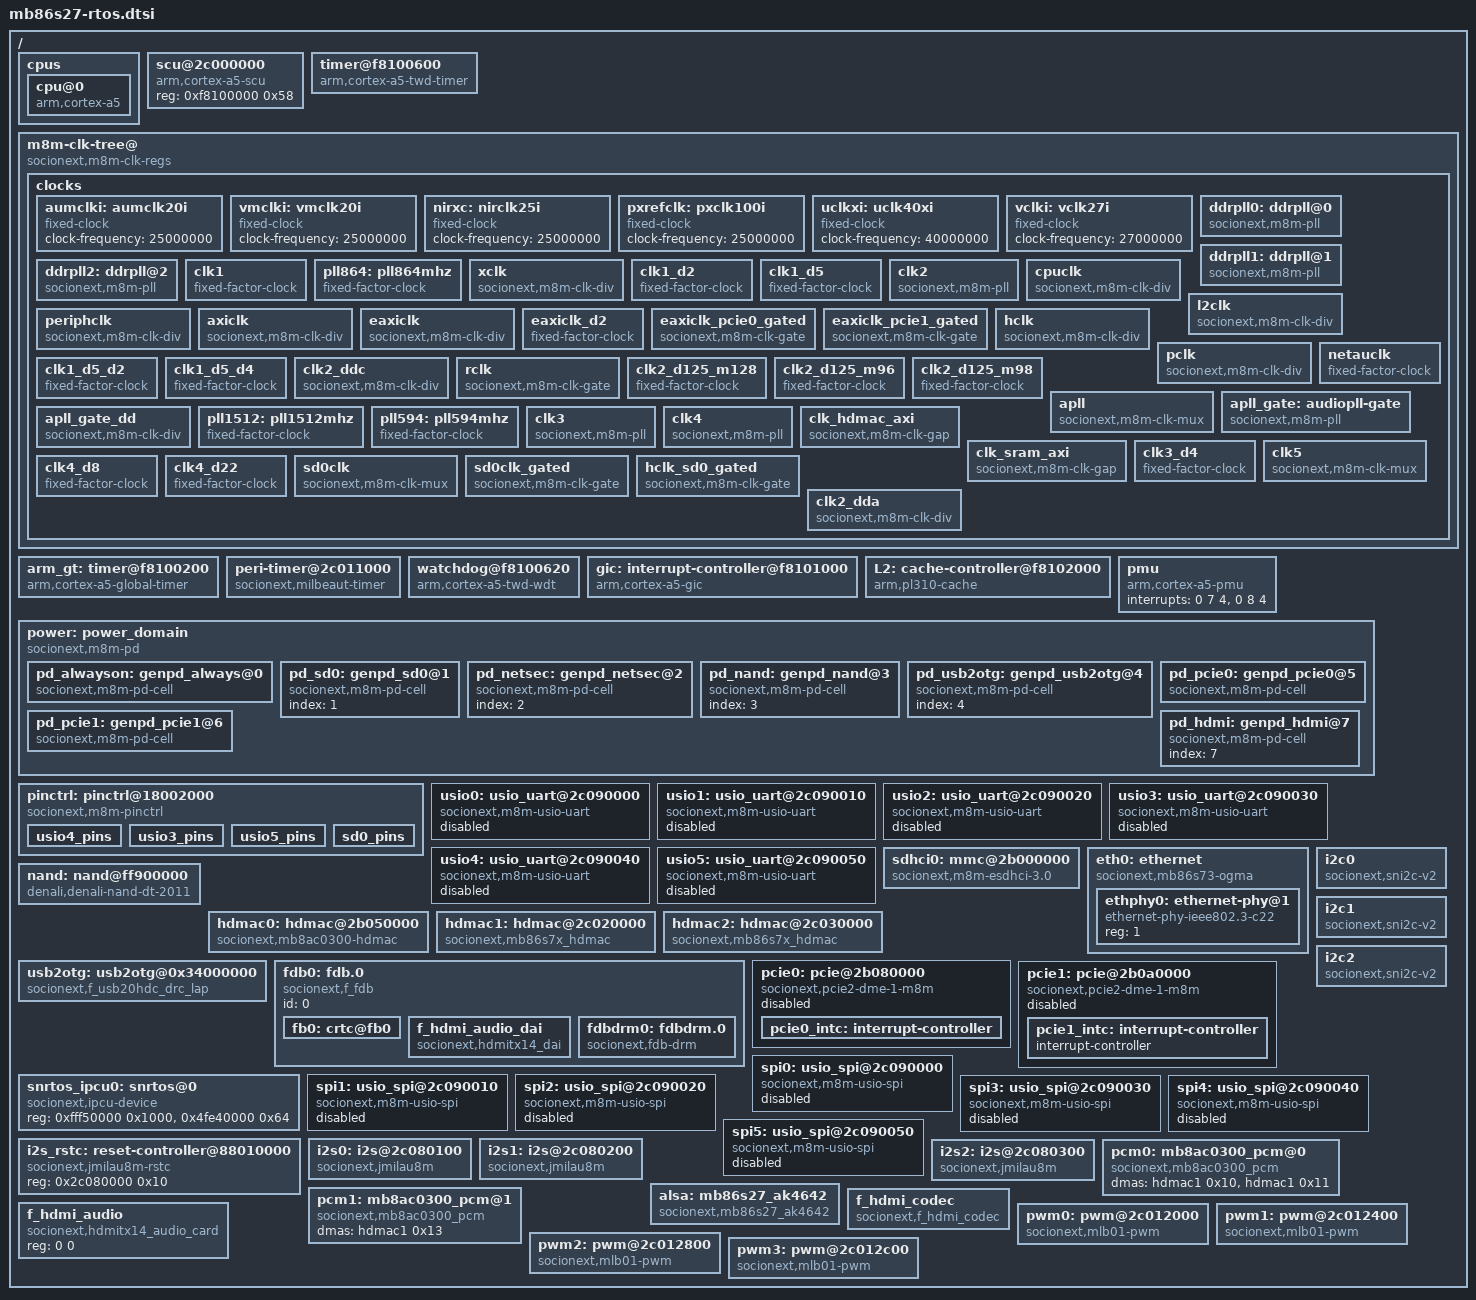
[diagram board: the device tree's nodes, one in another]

#include "skeleton.dtsi"
#include "mb86s27-clk.h"
#include <dt-bindings/interrupt-controller/irq.h>
#include <dt-bindings/gpio/gpio.h>
#include "mb86s27-gpios.h"

/ {
	cpus {
		#address-cells = <1>;
		#size-cells = <0>;
		cpu@0 {
			device_type = "cpu";
			compatible = "arm,cortex-a5";
			reg = <0>;

			operating-points = <
				/* kHz    uV */
				 400000 1000000
				 200000  980000
			>;

			clocks = <&cpuclk>;
			clock-names = "cpu";
			clock-latency = <10000>;

			next-level-cache = <&L2>;
		};
	};

	scu@2c000000 {
		compatible = "arm,cortex-a5-scu";
		reg = <0xf8100000 0x58>;
	};

	timer@f8100600 {
		compatible = "arm,cortex-a5-twd-timer";
		reg = <0xf8100600 0x20>;
		interrupts = <1 13 0x304>;
		clocks = <&periphclk>;
	};

	m8m-clk-tree@ {
		compatible = "socionext,m8m-clk-regs";
		reg = <0x18001000 0x1000>;
		blacklist-clksel = < /* 0x18001000+, '1' = illegal */
			0xff0fffff /* CLKSEL_A */
			0xffffffff /* CLKSEL_B */
			0xffffffff /* CLKSEL_C */
			0xffffffff /* CLKSEL_D */
			0xffe0e0e0 /* CLKSEL_E */
			0xe0e0e0e0 /* CLKSEL_F */
			0xfffffffe /* CLKSEL_G */
			0xffffffff /* CLKSEL_H */
			0xffffffff /* PLLCNTL */
			0xffffffff /* PLLCNTL2 */
			0xffffffff
			0xffffffff
			0xffffffff
			0xffffffff
			0xffffffff
			0xffffffff
			0xffffffff /* CRSWR */
			0xffffffff /* CRRRS */
			0xffffffff /* CRRSM */
		>;
		blacklist-clkstops = < /* 0x18001128+, '1' = illegal */
			0xf3f7bff5 /* CLKSTOPS_A */
			0xfffffcfe /* CLKSTOPS_B */
			0xffffffff /* CLKSTOPS_C */
			0xffffffff /* CLKSTOPS_D */
			0xffffffff /* CLKSTOPS_E */
			0xffffffff /* CLKSTOPS_F */
		>;
		blacklist-clkstopc = < /* 0x18001228+, '1' = illegal */
			0xf3f7bff5 /* CLKSTOPS_A */
			0xfffffcfe /* CLKSTOPS_B */
			0xffffffff /* CLKSTOPS_C */
			0xffffffff /* CLKSTOPS_D */
			0xffffffff /* CLKSTOPS_E */
			0xffffffff /* CLKSTOPS_F */
		>;

		clocks {
			#address-cells = <0>;
			#size-cells = <0>;

			aumclki: aumclk20i {
				compatible = "fixed-clock";
				#clock-cells = <0>;
				clock-frequency = <25000000>;
			};

			vmclki: vmclk20i {
				compatible = "fixed-clock";
				#clock-cells = <0>;
				clock-frequency = <25000000>;
			};

			nirxc: nirclk25i {
				compatible = "fixed-clock";
				#clock-cells = <0>;
				clock-frequency = <25000000>;
			};

			pxrefclk: pxclk100i {
				compatible = "fixed-clock";
				#clock-cells = <0>;
				clock-frequency = <25000000>;
			};

			uclkxi: uclk40xi {
				compatible = "fixed-clock";
				#clock-cells = <0>;
				clock-frequency = <40000000>;
			};

			vclki: vclk27i {
				compatible = "fixed-clock";
				#clock-cells = <0>;
				clock-frequency = <27000000>;
			};

			ddrpll0: ddrpll@0 {
				compatible = "socionext,m8m-pll";
				#clock-cells = <0>;
				offset = <bDDRPLL0ST>;
				rate-control = <bDDRPLL0SEL>;
				clocks = <&uclkxi>;
			};

			ddrpll1: ddrpll@1 {
				compatible = "socionext,m8m-pll";
				#clock-cells = <0>;
				offset = <bDDRPLL1ST>;
				rate-control = <bDDRPLL1SEL>;
				clocks = <&uclkxi>;
			};

			ddrpll2: ddrpll@2 {
				compatible = "socionext,m8m-pll";
				#clock-cells = <0>;
				offset = <bDDRPLL2ST>;
				rate-control = <bDDRPLL2SEL>;
				clocks = <&uclkxi>;
			};
/*
			cecclk: cecclk {
				compatible = "fixed-factor-clock";
				#clock-cells = <0>;
				clock-div = <20>;
				clock-mult = <1>;
				clocks = <&uclkxi>;
			};

			cecclk_gated: cecclk_gated {
				compatible = "socionext,m8m-clk-gate";
				#clock-cells = <0>;
				offset = <bCECCLK>;
				clocks = <&cecclk>;
			};
*/
			clk1: clk1 {
				compatible = "fixed-factor-clock";
				#clock-cells = <0>;
				clock-div = <2>;
				clock-mult = <100>;
				clocks = <&uclkxi>;
			};

			pll864: pll864mhz {
				compatible = "fixed-factor-clock";
				#clock-cells = <0>;
				clock-div = <5>;
				clock-mult = <108>;
				clocks = <&uclkxi>;
			};

			xclk: xclk {
				compatible = "socionext,m8m-clk-div";
				#clock-cells = <0>;
				offset = <bXCLK>;
				mask = <0x3>;
				ratios = <8 0x7 6 0x5 5 0x4>;
				clocks = <&clk1>;
			};

/*			dspclk: dspclk {
				compatible = "socionext,m8m-clk-div";
				#clock-cells = <0>;
				offset = <bDSPCLK>;
				mask = <0xf>;
				ratios = <12 0x1b 11 0x1a 10 0x19 9 0x18 8 0x17 7 0x16 6 0x15>;
				clocks = <&clk1>;
			};
*/
			clk1_d2: clk1_d2 {
				compatible = "fixed-factor-clock";
				#clock-cells = <0>;
				clock-div = <2>;
				clock-mult = <1>;
				clocks = <&clk1>;
			};

			clk1_d5: clk1_d5 {
				compatible = "fixed-factor-clock";
				#clock-cells = <0>;
				clock-div = <5>;
				clock-mult = <1>;
				clocks = <&clk1>;
			};

			clk2: clk2 {
				compatible = "socionext,m8m-pll";
				#clock-cells = <0>;
				offset = <bPLL864ST>;
				clocks = <&pll864>;
			};

			cpuclk: cpuclk {
				compatible = "socionext,m8m-clk-div";
				#clock-cells = <0>;
				offset = <bCPUCLK>;
				mask = <0xf>;
				wait-on-dchreq;
				ratios = <6 0x15 4 0x13 3 0x12 2 0x11 1 0x10>;
				clocks = <&xclk>;
			};

			l2clk: l2clk {
				compatible = "socionext,m8m-clk-div";
				#clock-cells = <0>;
				offset = <bL2CLK>;
				mask = <0xf>;
				wait-on-dchreq;
				ratios = <6 0x15 4 0x13 3 0x12 2 0x11>;
				clocks = <&xclk>;
			};

			periphclk: periphclk {
				compatible = "socionext,m8m-clk-div";
				#clock-cells = <0>;
				offset = <bPERICLK>;
				mask = <0xf>;
				wait-on-dchreq;
				ratios = <12 0x1b 8 0x17 6 0x15 4 0x13>;
				clocks = <&xclk>;
			};

			axiclk: axiclk {
				compatible = "socionext,m8m-clk-div";
				#clock-cells = <0>;
				offset = <bAXICLK>;
				mask = <0xf>;
				wait-on-dchreq;
				ratios = <6 0x15 4 0x13 3 0x12 2 0x11>;
				clocks = <&xclk>;
			};

			eaxiclk: eaxiclk {
				compatible = "socionext,m8m-clk-div";
				#clock-cells = <0>;
				offset = <bEAXICLK>;
				mask = <0xf>;
				wait-on-dchreq;
				ratios = <6 0x15 4 0x13 3 0x12 2 0x11>;
				clocks = <&xclk>;
			};

			eaxiclk_d2: eaxiclk_d2 {
				compatible = "fixed-factor-clock";
				#clock-cells = <0>;
				clock-div = <2>;
				clock-mult = <1>;
				clocks = <&eaxiclk>;
			};

			eaxiclk_pcie0_gated: eaxiclk_pcie0_gated {
				compatible = "socionext,m8m-clk-gate";
				#clock-cells = <0>;
				offset = <bPCIE0AX>;
				clocks = <&eaxiclk>;
			};

			eaxiclk_pcie1_gated: eaxiclk_pcie1_gated {
				compatible = "socionext,m8m-clk-gate";
				#clock-cells = <0>;
				offset = <bPCIE1AX>;
				clocks = <&eaxiclk>;
			};

			hclk: hclk {
				compatible = "socionext,m8m-clk-div";
				#clock-cells = <0>;
				offset = <bAHBCLK>;
				mask = <0xf>;
				wait-on-dchreq;
				ratios = <6 0x15 4 0x13 3 0x12>;
				clocks = <&xclk>;
			};

			pclk: pclk {
				compatible = "socionext,m8m-clk-div";
				#clock-cells = <0>;
				offset = <bAPBCLK>;
				mask = <0xf>;
				wait-on-dchreq;
				ratios = <12 0x1b 8 0x17 6 0x15>;
				clocks = <&xclk>;
			};

			netauclk: netauclk {
				compatible = "fixed-factor-clock";
				#clock-cells = <0>;
				clock-div = <8>;
				clock-mult = <1>;
				clocks = <&clk1_d2>;
			};
/*
			clk1_d2_cd: clk1_d2_cd {
				compatible = "socionext,m8m-clk-fine-div";
				#clock-cells = <0>;
				offset = <bPROCLK>;
				mask = <0x3f>;
				ratios = <75 5>;
				clocks = <&clk1_d2>;
			};
*/
			clk1_d5_d2: clk1_d5_d2 {
				compatible = "fixed-factor-clock";
				#clock-cells = <0>;
				clock-div = <2>;
				clock-mult = <1>;
				clocks = <&clk1_d5>;
			};

			clk1_d5_d4: clk1_d5_d4 {
				compatible = "fixed-factor-clock";
				#clock-cells = <0>;
				clock-div = <4>;
				clock-mult = <1>;
				clocks = <&clk1_d5>;
			};
/*
			clk1_d5_ddb: clk1_d5_ddb {
				compatible = "socionext,m8m-clk-div";
				#clock-cells = <0>;
				offset = <bSD1U1CLK>;
				mask = <0x7>;
				ratios = <4 0x8 2 0x9>;
				clocks = <&clk1_d5>;
			};

			sd1u1clk_gated: sd1u1clk_gated {
				compatible = "socionext,m8m-clk-gate";
				#clock-cells = <0>;
				offset = <bSD1U1CK>;
				clocks = <&clk1_d5_ddb>;
			};

			eaxiclk_sd1_gated: eaxiclk_sd1_gated {
				compatible = "socionext,m8m-clk-gate";
				#clock-cells = <0>;
				offset = <bSD1AX>;
				clocks = <&eaxiclk>;
			};

			clk1_d5_d2_cga: clk1_d5_d2_cga {
				compatible = "socionext,m8m-clk-gap";
				#clock-cells = <0>;
				offset = <bSROCLK>;
				clocks = <&clk1_d5_d2>;
			};

			clk1_d5_d2_cgb: clk1_d5_d2_cgb {
				compatible = "socionext,m8m-clk-gap";
				#clock-cells = <0>;
				offset = <bB2YCLK>;
				or-mask = <2>;
				clocks = <&clk1_d5_d2>;
			};

			clk1_d5_d2_cgc: clk1_d5_d2_cgc {
				compatible = "socionext,m8m-clk-gap";
				#clock-cells = <0>;
				offset = <bWDRCLK>;
				clocks = <&clk1_d5_d2>;
			};

			clk1_d5_d2_cgd: clk1_d5_d2_cgd {
				compatible = "socionext,m8m-clk-gap";
				#clock-cells = <0>;
				offset = <bAHIPCLK>;
				clocks = <&clk1_d5_d2>;
			};

			clk1_d5_d2_cge: clk1_d5_d2_cge {
				compatible = "socionext,m8m-clk-gap";
				#clock-cells = <0>;
				offset = <bJHDRCLK>;
				clocks = <&clk1_d5_d2>;
			};

			clk1_d5_d4_cg: clk1_d5_d4_cg {
				compatible = "socionext,m8m-clk-gap";
				#clock-cells = <0>;
				offset = <bJPGCLK>;
				clocks = <&clk1_d5_d4>;
			};

			clk2_ddb: clk2_ddb {
				compatible = "socionext,m8m-clk-div";
				#clock-cells = <0>;
				offset = <bSENCLK>;
				mask = <0x3>;
				ratios = <128 0x7 64 0x6 32 0x5 28 0x4>;
				clocks = <&clk2>;
			};
			*/
			clk2_ddc: clk2_ddc {
				compatible = "socionext,m8m-clk-div";
				#clock-cells = <0>;
				offset = <bRCLK>;
				mask = <0x3>;
				ratios = <64 0x4 48 0x5 32 0x6 16 0x7>;
				default = <64>;
				clocks = <&clk2>;
			};
			rclk: rclk {
				compatible = "socionext,m8m-clk-gate";
				#clock-cells = <0>;
				offset = <bRCK>;
				clocks = <&clk2_ddc>;
			};
/*
			i2cclk: i2cclk {
				compatible = "fixed-factor-clock";
				#clock-cells = <0>;
				clock-div = <2>;
				clock-mult = <1>;
				clocks = <&rclk>;
			};
			clk2_ddd: clk2_ddd {
				compatible = "socionext,m8m-clk-div";
				#clock-cells = <0>;
				offset = <bAPCLKO>;
				mask = <0x1f>;
				ratios = <16 0x38 12 0x39>;
				clocks = <&clk2>;
			};
*/
			clk2_d125_m128: clk2_d125_m128 {
				compatible = "fixed-factor-clock";
				#clock-cells = <0>;
				clock-div = <125>;
				clock-mult = <128>;
				clocks = <&clk2>;
			};

			clk2_d125_m96: clk2_d125_m96 {
				compatible = "fixed-factor-clock";
				#clock-cells = <0>;
				clock-div = <125>;
				clock-mult = <96>;
				clocks = <&clk2>;
			};

			clk2_d125_m98: clk2_d125_m98 {
				compatible = "fixed-factor-clock";
				#clock-cells = <0>;
				clock-div = <125>;
				clock-mult = <98>;
				clocks = <&clk2>;
			};

			apll: apll { // model the pll as a mux 
				compatible = "socionext,m8m-clk-mux";
				#clock-cells = <0>;
				offset = <bAPLSEL>;
				clocks = <&clk2_d125_m128>,
					 <&clk2_d125_m96>,
					 <&clk2_d125_m98>;
				mux = <0x0 0x2 0x3>;
				mask = <0x3>;
			};

			apll_gate: audiopll-gate {
				compatible = "socionext,m8m-pll";
				#clock-cells = <0>;
				offset = <bAPLLST>;
				clocks = <&apll>;
			};


			apll_gate_dd: apll_gate_dd {
				compatible = "socionext,m8m-clk-div";
				#clock-cells = <0>;
				offset = <bAPLCLK>;
				mask = <0x3>;
				ratios = <108 0x4 36 0x6 30 0x5 18 0x7>;
				clocks = <&apll_gate>;
			};
			pll1512: pll1512mhz {
				compatible = "fixed-factor-clock";
				#clock-cells = <0>;
				clock-div = <1>;
				clock-mult = <56>;
				clocks = <&vclki>;
			};

			pll594: pll594mhz {
				compatible = "fixed-factor-clock";
				#clock-cells = <0>;
				clock-div = <1>;
				clock-mult = <22>;
				clocks = <&vclki>;
			};

			clk3: clk3 {
				compatible = "socionext,m8m-pll";
				#clock-cells = <0>;
				offset = <bPLL1512ST>;
				clocks = <&pll1512>;
			};

			clk4: clk4 {
				compatible = "socionext,m8m-pll";
				#clock-cells = <0>;
				offset = <bPLL594ST>;
				clocks = <&pll594>;
			};
/*

			clk3_dda: clk3_dda {
				compatible = "socionext,m8m-clk-div";
				#clock-cells = <0>;
				offset = <bNFCLK>;
				mask = <0x1>;
				ratios = <4 0x2 2 0x3>;
				default = <2>;
				clocks = <&clk3>;
			};

			clk_axinf: clk_axinf {
				compatible = "socionext,m8m-clk-gap";
				#clock-cells = <0>;
				offset = <bNFAX>;
				clocks = <&axiclk>;
			};
			clk_xdmac_axi: clk_xdmac_axi {
				compatible = "socionext,m8m-clk-gap";
				#clock-cells = <0>;
				offset = <bXDMEAX>;
				clocks = <&axiclk>;
			};
*/
			clk_hdmac_axi: clk_hdmac_axi {
				compatible = "socionext,m8m-clk-gap";
				#clock-cells = <0>;
				offset = <bHDMEAH>;
				clocks = <&axiclk>;
			};

			clk_sram_axi: clk_sram_axi {
				compatible = "socionext,m8m-clk-gap";
				#clock-cells = <0>;
				offset = <bSRAMAX>;
				clocks = <&axiclk>;
			};


			clk3_d4: clk3_d4 {
				compatible = "fixed-factor-clock";
				#clock-cells = <0>;
				clock-div = <4>;
				clock-mult = <1>;
				clocks = <&clk3>;
			};
/*
			clk3_d3: clk3_d3 {
				compatible = "fixed-factor-clock";
				#clock-cells = <0>;
				clock-div = <3>;
				clock-mult = <1>;
				clocks = <&clk3>;
			};

			clk3_d3_dd: clk3_d3_dd {
				compatible = "socionext,m8m-clk-div";
				#clock-cells = <0>;
				offset = <bAPCLKO>;
				mask = <0x1f>;
				ratios = <18 0x30 8 0x31>;
				clocks = <&clk3_d3>;
			};

			clk3_d2: clk3_d2 {
				compatible = "fixed-factor-clock";
				#clock-cells = <0>;
				clock-div = <2>;
				clock-mult = <1>;
				clocks = <&clk3>;
			};

			clk3_d2_d30: clk3_d2_d30 {
				compatible = "fixed-factor-clock";
				#clock-cells = <0>;
				clock-div = <30>;
				clock-mult = <1>;
				clocks = <&clk3_d2>;
			};

			clk3_d2_cda: clk3_d2_cda {
				compatible = "socionext,m8m-clk-fine-div";
				#clock-cells = <0>;
				offset = <bLCDCLK>;
				mask = <0x3f>;
				ratios = <128 14>;
				default = <128>;
				clocks = <&clk3_d2>;
			};
			clk3_d2_cdb: clk3_d2_cdb {
				compatible = "socionext,m8m-clk-fine-div";
				#clock-cells = <0>;
				offset = <bSD1U2CLK>;
				mask = <0x1f>;
				ratios = <29 15>;
				delta = <0x20>;
				clocks = <&clk3_d2>;
			};

			sd1u2clk_gated: sd1u2clk_gated {
				compatible = "socionext,m8m-clk-gate";
				#clock-cells = <0>;
				offset = <bSD1U2CK>;
				clocks = <&clk3_d2_cdb>;
			};
			clk3_d2_cdc: clk3_d2_cdc {
				compatible = "socionext,m8m-clk-fine-div";
				#clock-cells = <0>;
				offset = <bPROCLK>;
				mask = <0x3f>;
				ratios = <75 4>;
				clocks = <&clk3_d2>;
			};

			clk3_d6: clk3_d6 {
				compatible = "fixed-factor-clock";
				#clock-cells = <0>;
				clock-div = <6>;
				clock-mult = <1>;
				clocks = <&clk3>;
			};

			clk3_d6_cga: clk3_d6_cga {
				compatible = "socionext,m8m-clk-gap";
				#clock-cells = <0>;
				offset = <bSROCLK>;
				clocks = <&clk3_d6>;
			};

			clk3_d6_cgb: clk3_d6_cgb {
				compatible = "socionext,m8m-clk-gap";
				#clock-cells = <0>;
				offset = <bSPRCLK>;
				clocks = <&clk3_d6>;
			};

			clk3_d6_cgc: clk3_d6_cgc {
				compatible = "socionext,m8m-clk-gap";
				#clock-cells = <0>;
				offset = <bIIPCLK>;
				clocks = <&clk3_d6>;
			};

			clk3_d6_cgd: clk3_d6_cgd {
				compatible = "socionext,m8m-clk-gap";
				#clock-cells = <0>;
				offset = <bELA0CLK>;
				clocks = <&clk3_d6>;
			};

			clk3_d6_cge: clk3_d6_cge {
				compatible = "socionext,m8m-clk-gap";
				#clock-cells = <0>;
				offset = <bELA1CLK>;
				clocks = <&clk3_d6>;
			};

			clk3_d6_cgf: clk3_d6_cgf {
				compatible = "socionext,m8m-clk-gap";
				#clock-cells = <0>;
				offset = <bDPPCLK>;
				clocks = <&clk3_d6>;
			};

			clk3_d6_cgg: clk3_d6_cgg {
				compatible = "socionext,m8m-clk-gap";
				#clock-cells = <0>;
				offset = <bSRRCLK>;
				clocks = <&clk3_d6>;
			};

			clk3_d6_cgh: clk3_d6_cgh {
				compatible = "socionext,m8m-clk-gap";
				#clock-cells = <0>;
				offset = <bAHFDCLK>;
				clocks = <&clk3_d6>;
			};

			clk4_dda: clk4_dda {
				compatible = "socionext,m8m-clk-div";
				#clock-cells = <0>;
				offset = <bAPCLKO>;
				mask = <0x1f>;
				ratios = <55 0x20 52 0x21 50 0x22 24 0x23 21 0x24 16 0x25 15 0x26 14 0x27 13 0x28 12 0x29 10 0x2a 8 0x2b>;
				clocks = <&clk4>;
			};

			clk4_d2: clk4_d2 {
				compatible = "fixed-factor-clock";
				#clock-cells = <0>;
				clock-div = <2>;
				clock-mult = <1>;
				clocks = <&clk4>;
			};

			clk4_d2_cg: clk4_d2_cg {
				compatible = "socionext,m8m-clk-gap";
				#clock-cells = <0>;
				offset = <bSROCLK>;
				clocks = <&clk4_d2>;
			};

			aplclk0: aplclk0 {
				compatible = "socionext,m8m-clk-mux";
				#clock-cells = <0>;
				offset = <bAU0CKSEL>;
				clocks = <&apll_gate_dd>, <&aumclki>;
				mux = <0x2 0x3>;
				mask = <0x1>;
			};

			aplclk1: aplclk1 {
				compatible = "socionext,m8m-clk-mux";
				#clock-cells = <0>;
				offset = <bAU1CKSEL>;
				clocks = <&apll_gate_dd>, <&aumclki>;
				mux = <0x2 0x3>;
				mask = <0x1>;
			};

			aplclk2: aplclk2 {
				compatible = "socionext,m8m-clk-mux";
				#clock-cells = <0>;
				offset = <bAU2CKSEL>;
				clocks = <&apll_gate_dd>, <&aumclki>;
				mux = <0x2 0x3>;
				mask = <0x1>;
			};

			aplclk0_gated: aplclk0_gated {
				compatible = "socionext,m8m-clk-gate";
				#clock-cells = <0>;
				offset = <bAU0CK>;
				clocks = <&aplclk0>;
			};

			aplclk1_gated: aplclk1_gated {
				compatible = "socionext,m8m-clk-gate";
				#clock-cells = <0>;
				offset = <bAU1CK>;
				clocks = <&aplclk1>;
			};

			aplclk2_gated: aplclk2_gated {
				compatible = "socionext,m8m-clk-gate";
				#clock-cells = <0>;
				offset = <bAU2CK>;
				clocks = <&aplclk2>;
			};
			dispax: dispax {
				compatible = "socionext,m8m-clk-gate";
				#clock-cells = <0>;
				offset = <bDISPAX>;
				clocks = <&axiclk>;
			};
			dispah: dispah {
				compatible = "socionext,m8m-clk-gate";
				#clock-cells = <0>;
				offset = <bDISPAH>;
				clocks = <&axiclk>;
			};
			dispap: dispap {
				compatible = "socionext,m8m-clk-gate";
				#clock-cells = <0>;
				offset = <bDISPAP>;
				clocks = <&axiclk>;
			};
*/
			clk5: clk5 {
				compatible = "socionext,m8m-clk-mux";
				#clock-cells = <0>;
				offset = <bNETAUCKSEL>;
				clocks = <&apll_gate_dd>, <&aumclki>;
				mux = <0x2 0x3>;
				mask = <0x1>;
			};
/*
			lcdclk: lcdclk {
				compatible = "socionext,m8m-clk-mux";
				#clock-cells = <0>;
				offset = <bLCDSEL>;
				clocks = <&clk3_d2_cda>, <&vmclki>, <&vclki>;
				mux = <0x4 0x6 0x7>;
				mask = <0x3>;
			};
			lcdclk_gated: lcdclk_gated {
				compatible = "socionext,m8m-clk-gate";
				#clock-cells = <0>;
				offset = <bLCDCK>;
				clocks = <&lcdclk>;
			};
*/

			clk4_d8: clk4_d8 {
				compatible = "fixed-factor-clock";
				#clock-cells = <0>;
				clock-div = <22>;
				clock-mult = <1>;
				clocks = <&clk4>;
			};

			clk4_d22: clk4_d22 {
				compatible = "fixed-factor-clock";
				#clock-cells = <0>;
				clock-div = <22>;
				clock-mult = <1>;
				clocks = <&clk4>;
			};

/*
			hifclk: hifclk {
				compatible = "socionext,m8m-clk-mux";
				#clock-cells = <0>;
				offset = <bHIFCLK>;
				clocks = <&clk4_d8>, <&clk4_d22>, <&clk3_d2_d30>, <&vmclki>, <&vclki>;
				mux = <0x8 0x9 0xa 0xc 0xe>;
				mask = <0x7>;
			};
			hifclk_gated: hifclk_gated {
				compatible = "socionext,m8m-clk-gate";
				#clock-cells = <0>;
				offset = <bHIFCK>;
				clocks = <&hifclk>;
			};
*/

			sd0clk: sd0clk {
				compatible = "socionext,m8m-clk-mux";
				#clock-cells = <0>;
				offset = <bSD0CLK>;
				clocks = <&clk1_d5_d4>, <&clk4>, <&clk3_d4>, <&clk1_d5_d2>;
				mux = <0x8 0xc 0xa 0x9>;
				mask = <0x7>;
			};

			sd0clk_gated: sd0clk_gated {
				compatible = "socionext,m8m-clk-gate";
				#clock-cells = <0>;
				offset = <bSD0CK>;
				clocks = <&sd0clk>;
			};

			hclk_sd0_gated: hclk_sd0_gated {
				compatible = "socionext,m8m-clk-gate";
				#clock-cells = <0>;
				offset = <bSD0AH>;
				clocks = <&hclk>;
			};

			clk2_dda: clk2_dda {
				compatible = "socionext,m8m-clk-div";
				#clock-cells = <0>;
				offset = <bRIBCLK>;
				mask = <0xf>;
				ratios = <64 0x10 32 0x11 16 0x12 8 0x13 4 0x14>;
				clocks = <&clk2>;
			};
/*
			clk3_ddb: clk3_ddb {
				compatible = "socionext,m8m-clk-div";
				#clock-cells = <0>;
				offset = <bRIBCLK>;
				mask = <0xf>;
				ratios = <12 0x18 8 0x19 6 0x1a 5 0x1b>;
				clocks = <&clk3>;
			};
			ribclk: ribclk {
				compatible = "socionext,m8m-clk-mux";
				#clock-cells = <0>;
				clocks = <&clk2_dda>, <&clk3_ddb>;
			};

			apclko0: apclko0 {
				compatible = "socionext,m8m-clk-mux";
				#clock-cells = <0>;
				clocks = <&clk2_ddd>, <&clk4_dda>, <&clk3_d3_dd>;
			};

			proclk: proclk {
				compatible = "socionext,m8m-clk-mux";
				#clock-cells = <0>;
				offset = <bPROMUX>;
				clocks = <&clk1_d2_cd>, <&clk3_d2_cdc>;
				mux = <0x2 0x3>;
				mask = <0x1>;
			};

			srosel: srosel {
				compatible = "socionext,m8m-clk-mux";
				#clock-cells = <0>;
				offset = <bSROSEL>;
				clocks = <&clk4_d2_cg>, <&proclk>, <&clk3_d6_cga>, <&clk1_d5_d2_cga>;
				mux = <0x4 0x5 0x6 0x7>;
				mask = <0x3>;
			};

			b2yclk: b2yclk {
				compatible = "socionext,m8m-clk-mux";
				#clock-cells = <0>;
				offset = <bB2YCLK>;
				clocks = <&clk1_d5_d2_cgb>, <&proclk>;
				mux = <0x0 0x18>;
				mask = <0xf>;
			};
*/
		};
	};

	arm_gt: timer@f8100200 {
		compatible = "arm,cortex-a5-global-timer",
		             "arm,cortex-a9-global-timer";
		reg = <0xf8100200 0x20>;
		interrupts = <1 11 0x304>;
		clocks = <&periphclk>;
	};

	peri-timer@2c011000 {
		compatible = "socionext,milbeaut-timer";
		reg = <0x2c011050 0x10>, <0x2c011060 0x10>;
		interrupts = <0 127 4>;
		clocks = <&clk2_dda>; /* RIBCLK */
	};

	watchdog@f8100620 {
		compatible = "arm,cortex-a5-twd-wdt";
		reg = <0xf8100620 0x20>;
		interrupts = <1 14 0x304>;
	};

	gic: interrupt-controller@f8101000 {
		compatible = "arm,cortex-a5-gic", "arm,cortex-a9-gic";
		#interrupt-cells = <3>;
		#address-cells = <0>;
		interrupt-controller;
		reg = <0xf8101000 0x1000>,
		      <0xf8100100 0x100>;
		black-list = <0 1 2 3 4 5 6 7 8 9 10 11 12 13 14 15 16 17 18 19 20 21 22 23 24 25 26 27 28 29 30 31 32 33 34 35 36 37 38 39 40 41 42 43 44 45 46 47 48 49 50 51 52 53 54 55 56 57 58 59 60 61 62 63 64 65 66 67 68 69 70 71 72 73 74 75 76 77 78 79 80 81 82 83 84 85 86 87 88 89 90 91 92 93 94 95 96 97 98 99 100 101 102 103 104 105 106 107 108 109 110 111 112 113 114 115 116 117 118 119 120 121 122 123 124 125 126 127 128 129 130 131 132 133 134 135 136 137 138 139 140 141 142 143 144 145 146 147 148 149 150 151 152 153 154 155 156 157 158 159 160 161 162 163 164 165 166 167 168 169 170 171 172 173 174 175 176 177 178 179 180 181 182 183 184 185 186 187 188 189 190 191>;

	};

	L2: cache-controller@f8102000 {
		compatible = "arm,pl310-cache";
		reg = <0xf8102000 0x1000>;
		interrupts = <0 6 4>;
		cache-level = <2>;
		cache-unified;
		clocks = <&l2clk>;
	};

	pmu {
		compatible = "arm,cortex-a5-pmu";
		interrupts = <0 7 4>,
			     <0 8 4>;
	};

	power: power_domain {
		compatible = "socionext,m8m-pd";
        	reg =  <0x18000000 0x4000>, /* top jtscr */
			<0x29000000 0x2000>, /* gpv */
        		<0xf8000000 0x1000>, /* nic */
			<0x2B110000 0x1000>; /* exs */

		#power-domain-cells = <1>;
		#address-cells = <1>;
		#size-cells = <1>;
		ranges;
 
		pd_alwayson: genpd_always@0 {
			compatible = "socionext,m8m-pd-cell";
			index = <0>;
			clocks = <&ddrpll0>, <&ddrpll1>, <&ddrpll2>,
				<&clk5>, <&netauclk>;
		};
		pd_sd0: genpd_sd0@1 {
			compatible = "socionext,m8m-pd-cell";
			index = <1>;
		};
		pd_netsec: genpd_netsec@2 {
			compatible = "socionext,m8m-pd-cell";
			index = <2>;
		};
		pd_nand: genpd_nand@3 {
			compatible = "socionext,m8m-pd-cell";
			index = <3>;
		};
		pd_usb2otg: genpd_usb2otg@4 {
			compatible = "socionext,m8m-pd-cell";
			index = <4>;
		};
		pd_pcie0: genpd_pcie0@5 {
			compatible = "socionext,m8m-pd-cell";
			index = <5>;
			clocks = <&eaxiclk_pcie0_gated>;
		};
		pd_pcie1: genpd_pcie1@6 {
			compatible = "socionext,m8m-pd-cell";
			index = <6>;
			master-domain-cell = <&pd_pcie0>;
			clocks = <&eaxiclk_pcie1_gated>;
		};
		pd_hdmi: genpd_hdmi@7 {
			compatible = "socionext,m8m-pd-cell";
			index = <7>;
		};
/*

		pd_sd1: genpd_sd1@8 {
			compatible = "socionext,m8m-pd-cell";
			index = <8>;
			clocks = <&sd1u2clk_gated>;
		};
*/
	};

	pinctrl: pinctrl@18002000 {
		compatible = "socionext,m8m-pinctrl";
		reg = <0x18002000 0x1000>,
		      <0xfff6f000 0x1000>;
		reg-names = "pinctrl", "exiu";
		gpio-controller;
		#gpio-cells = <2>;
		interrupt-controller;
		#interrupt-cells = <2>;
		clocks = <&periphclk>;
		blacklist = < /* P3 thru PU, bit = 1 = illegal */
			0xff /* P3 */
			0xfd /* P4 */
			0xff /* P5 */
			0xff /* P6 */
			0xff /* P7 */
			0xe7 /* P8 */
			0xff /* P9 */
			0xd3 /* PA */
			0x00 /* PC */
			0xff /* PD */
			0xff /* PE */
			0xff /* PF */
			0xff /* PG */
			0xe0 /* PP */
			0xff /* PR */
			0xff /* PS */
			0xff /* PT */
			0xef /* PU */
		>;
/*		interrupts = <0 29 4>, <0 30 4>, <0 31 4>, <0 32 4>,
				<0 33 4>, <0 34 4>, <0 35 4>, <0 36 4>,
				<0 37 4>, <0 38 4>, <0 39 4>, <0 40 4>,
				<0 41 4>, <0 42 4>, <0 43 4>, <0 44 4>,
				<0 45 4>, <0 46 4>, <0 47 4>, <0 48 4>,
				<0 49 4>, <0 50 4>, <0 51 4>, <0 52 4>,
				<0 53 4>, <0 54 4>, <0 55 4>, <0 56 4>,
				<0 57 4>, <0 58 4>, <0 59 4>, <0 60 4>;
		interrupt-names = "pin-32", "pin-33", "pin-34", "pin-35",
				"pin-0", "pin-1", "pin-2", "pin-3",
				"pin-24", "pin-25", "pin-26", "pin-27",
				"pin-49", "pin-50", "pin-51", "pin-127",
				"pin-60", "pin-120", "pin-78", "pin-79",
				"pin-112", "pin-113", "pin-119", "pin-129",
				"pin-130", "pin-124", "pin-125", "pin-63",
				"pin-4", "pin-5", "pin-7", "pin-6";*/

		usio4_pins: usio4_pins {
			pins = "PA1", "PA2", "PA3";
			function = "usio4";
		};
		usio3_pins: usio3_pins { // add
			pins = "P83", "P84", "P85";	// FPSCK3=P85, FPSIN3=P84, FPSOUT3=P83
			function = "usio3";
		};

		usio5_pins: usio5_pins {
			pins = "PD5", "PD4", "PD3";
			function = "usio5";
		};

		sd0_pins: sd0_pins {
			pins = "PC2", "PC3", "PC4", "PC5", "PC6", "PC7", "PA5";
			function = "sd0";
		};
	};
	usio0: usio_uart@2c090000 {
		status = "disabled";
		compatible = "socionext,m8m-usio-uart";
		reg = <0x2c090000 0x10>;
		interrupts = <0 132 0x4>, <0 133 0x4>;
		interrupt-names = "rx", "tx";
		clocks = <&periphclk>;
		pinctrl-names = "default";
		pinctrl-0 = <&usio4_pins>;
	};
	usio1: usio_uart@2c090010 {
		status = "disabled";
		compatible = "socionext,m8m-usio-uart";
		reg = <0x2c090010 0x10>;
		interrupts = <0 134 0x4>, <0 135 0x4>;
		interrupt-names = "rx", "tx";
		clocks = <&periphclk>;
	};
	usio2: usio_uart@2c090020 {
		status = "disabled";
		compatible = "socionext,m8m-usio-uart";
		reg = <0x2c090020 0x10>;
		interrupts = <0 136 0x4>, <0 137 0x4>;
		interrupt-names = "rx", "tx";
		clocks = <&periphclk>;
	};
	usio3: usio_uart@2c090030 {
		status = "disabled";
		compatible = "socionext,m8m-usio-uart";
		reg = <0x2c090030 0x10>;
		interrupts = <0 138 0x4>, <0 139 0x4>;
		interrupt-names = "rx", "tx";
		clocks = <&periphclk>;
	};
	usio4: usio_uart@2c090040 {
		status = "disabled";
		compatible = "socionext,m8m-usio-uart";
		reg = <0x2c090040 0x10>;
		interrupts = <0 140 0x4>, <0 141 0x4>;
		interrupt-names = "rx", "tx";
		clocks = <&periphclk>;
	};
	usio5: usio_uart@2c090050 {
		status = "disabled";
		compatible = "socionext,m8m-usio-uart";
		reg = <0x2c090050 0x10>;
		interrupts = <0 142 0x4>, <0 143 0x4>;
		interrupt-names = "rx", "tx";
		clocks = <&periphclk>;
		pinctrl-names = "default";
		pinctrl-0 = <&usio5_pins>;
	};

	sdhci0: mmc@2b000000 { /* CH0 */
                compatible = "socionext,m8m-esdhci-3.0";
		reg = <0x2b000000 0x10000>;
		interrupts = <0 150 0x4>;
		bus-width = <4>;
		max-frequency = <208000000>;
		clocks = <&sd0clk_gated>, <&hclk_sd0_gated>;
		clock-names = "core", "iface";
		power-domains = <&power 1>;
		pinctrl-names = "default";
		pinctrl-0 = <&sd0_pins>;
		wp-gpios = <&pinctrl PC1 GPIO_ACTIVE_LOW>;
        };
/*
	sdhci1: mmc@2b010000 { // CH1 UHS-I 
                compatible = "socionext,m8m-esdhci-3.0";
		reg = <0x2b010000 0x10000>;
		interrupts = <0 144 0x4>;
		voltage-ranges = <3300 3300>;
		bus-width = <4>;
		clocks = <&sd1u2clk_gated>, <&eaxiclk_sd1_gated>;
		clock-names = "core", "iface";
		cap-sdio-irq;
		power-domains = <&power 8>;
	};
*/
	eth0: ethernet {
		compatible = "socionext,mb86s73-ogma", "socionext,ogma";
		reg = <0x2b100000 0x10000>, <0x8000 0>, <0xc000 0>;
		interrupts = <0 165 4>, <0 166 4>;
		phy-mode = "rgmii";
		max-speed = <1000>;
		max-frame-size = <9000>;
		local-mac-address = [ a4 17 31 88 00 ed ];
		phy-handle = <&ethphy0>;

		clocks = <&rclk>, <&netauclk>, <&clk5>;

		power-domains = <&power 2>;

		#address-cells = <1>;
		#size-cells = <0>;

		ethphy0: ethernet-phy@1 {
			device_type = "ethernet-phy";
			compatible = "ethernet-phy-ieee802.3-c22";
			reg = <1>;
		};
	};

	nand: nand@ff900000 {
	        #address-cells = <1>;
	        #size-cells = <1>;
	        compatible = "denali,denali-nand-dt-2011";
	        reg = <0x29100000 0x10000>, <0x29110000 0x10000>;
	        reg-names = "nand_data", "denali_reg";
	        interrupts = <0 153 4>;
	        dma-mask = <0xffffffff>;
		ecc-page0-strength = <4>; /* decided by device ROM */
		power-domains = <&power 3>;
/*
		clocks = <&clk3_dda>;
*/
	};

	hdmac0: hdmac@2b050000 { /* USB-related */
		compatible = "socionext,mb8ac0300-hdmac";
		reg = <0x2b050000 0x1000>;
		interrupts = <0 161 4>, /* used for USB */
			     <0 162 4>; /* used for USB */
			    // <0 163 4>,
			    // <0 164 4>;
		clocks = <&clk_hdmac_axi>;
		channels = <2>;
		chip = <0>;
		rotation = <1>;
		power-domains = <&power 0>;
	};

	hdmac1: hdmac@2c020000 { /* Audio-related IDREQs */
		compatible = "socionext,mb86s7x_hdmac";
		reg = <0x2c020000 0x1000>;
		interrupts = <0 89 4>,
			     <0 90 4>,
			     <0 91 4>,
			     <0 92 4>,
			     <0 93 4>,
			     <0 94 4>,
			     <0 95 4>,
			     <0 96 4>;
		#dma-cells = <1>;
		priority-rotate;
		clocks = <&clk_hdmac_axi>;
		power-domains = <&power 0>;
	};

	hdmac2: hdmac@2c030000 { /* USIO IDREQs */
		compatible = "socionext,mb86s7x_hdmac";
		reg = <0x2c030000 0x1000>;
		interrupts = <0 97 4>,
			     <0 98 4>,
			     <0 99 4>,
			     <0 100 4>,
			     <0 101 4>,
			     <0 102 4>,
			     <0 103 4>,
			     <0 104 4>;
		#dma-cells = <1>;
		priority-rotate;
		clocks = <&clk_hdmac_axi>;
		power-domains = <&power 0>;
	};

	usb2otg: usb2otg@0x34000000 {
		compatible = "socionext,f_usb20hdc_drc_lap";
		reg = <0x2b020000 0x31000>, <0x2b040000 0x10000>;
		interrupts = <0 154 0x4>;
		dma_dreq = <0x0e000000 0x0e000000>;
		hdmac_channel = <0 1>;
		clocks = <&hclk>, <&pclk>, <&pclk>, <&clk_sram_axi>;
		clock-names = "h_clk", "p_clk", "p_cryclk";
		power-domains = <&power 4>;
	};

	fdb0: fdb.0 {
		compatible = "socionext,f_fdb", "simple-bus";
		id = <0>;
		#address-cells = <1>;
		#size-cells = <1>;
		ranges;
/*
		videophy0: dpi@fb0 {
			compatible = "socionext,jdsdisp2b-dpi";
			reg = <0x20000000 0x8000>;
			interrupts = <0 305 0x4>;
			sources = <1>; // bitfield of fbs can be driven by 
			clocks = <&lcdclk_gated>;
			clock-names = "lcdclk";
		};

		videophy1: hdmitx14@fb1 {
			compatible = "socionext,f_hdmi_tx14";
			reg = <0x2c018000 0x9000>;
			interrupts = <0 88 4>;
			sources = <1>; // bitfield of fbs can be driven by 
			clocks = <&hifclk_gated>, <&pclk>, <&cecclk_gated>;
			power-domains = <&power 7>;
		};
*/
		fb0: crtc@fb0 {
/*			compatible = "socionext,jdsdisp2b";
			reg = <0x200f0000 0x8000>, <0x24000000 0x10000>;
			reg-names = "apb", "ahb";
			interrupts = <0 76 4>, <0 77 4>;
			id = <0>;
			clocks = <&lcdclk_gated>, <&hifclk_gated>,
				 <&dispax>, <&dispah>, <&dispap>, <&clk4_d8>,
				 <&vclki>;
			clock-names = "clk1", "clk2", "clk3",
					"clk4", "clk5", "clk6", "clk7";
			power-domains = <&power 7>;
*/
		};
        f_hdmi_audio_dai: f_hdmi_audio_dai {
                        compatible = "socionext,hdmitx14_dai";
			transport-dai = "2c080200.i2s";
                        reg = <0 0>;
         };

		fdbdrm0: fdbdrm.0 {
			compatible = "socionext,fdb-drm";
			bind = <&fb0>;
			registrations = <6>; /* wait for this many children */
			default-bpp = <32>;
		};
	};

	pcie0: pcie@2b080000 {
		status = "disabled";

		#address-cells = <3>;
		#size-cells = <2>;
		#interrupt-cells = <1>;
		compatible = "socionext,pcie2-dme-1-m8m";
		reg = <0x2b080000 0x8000>, <0x2a400000 0x40000>;
		device_type = "pci";
		power-domains = <&power 5>;
		linux,pci-domain = <0>;
		bus-range = <0 1>;

		interrupts = <0 167 4>, /* "own" */
			     <0 168 4>, /* Endpoint ... includes ACBD ints */
			     <0 169 4>, /* SYS_ERR */
			     <0 170 4>, /* DMA */
			     <0 171 4>; /* TRS, ICS, MSI */
		interrupt-map-mask = <0 0 0 15>;
		interrupt-map =
			<0 0 0 1 &pcie0_intc 1>,
			<0 0 0 2 &pcie0_intc 2>,
			<0 0 0 3 &pcie0_intc 3>,
			<0 0 0 4 &pcie0_intc 4>;

		ranges = 
			/*     bus address        parent ads        size */
			<0x02000000 0 0x00000000  0x2a000000  0 0x00400000
	/* config */	 0x00000000 0 0xC0000000  0x2a400000  0 0x00400000>;

		pcie0_intc: interrupt-controller {
			interrupt-controller;
			#address-cells = <0>;
			#interrupt-cells = <1>;
			interrupt-parent = <&gic>;
		};
	};

	pcie1: pcie@2b0a0000 {

		status = "disabled";

		#address-cells = <3>;
		#size-cells = <2>;
		#interrupt-cells = <1>;
		compatible = "socionext,pcie2-dme-1-m8m";
		reg = <0x2b0a0000 0x8000>;
		device_type = "pci";
		power-domains = <&power 6>;
		linux,pci-domain = <1>;
		bus-range = <0 1>;

		clocks = <&eaxiclk_pcie1_gated>;

		interrupts = < 0 172 4 >;
		interrupt-map-mask = <0 0 0 15>;
		interrupt-map =
			<0 0 0 1 &gic 0 173 4>,
			<0 0 0 2 &gic 0 174 4>,
			<0 0 0 3 &gic 0 175 4>,
			<0 0 0 4 &gic 0 176 4>;

		ranges = 
		/*	     bus address        parent ads        size */
			<0x02000000 0 0x80000000  0x2a800000  0 0x00400000
	/* config */	 0x02000000 0 0xC0000000  0x2ac00000  0 0x00010000>;

		pcie1_intc: interrupt-controller {
			interrupt-controller;
			#address-cells = <0>;
			#interrupt-cells = <1>;
		};
	};

	snrtos_ipcu0: snrtos@0 {
		compatible = "socionext,ipcu-device";
		reg = <0xfff50000 0x1000>, <0x4fe40000 0x64>;
	};

/*
	ipcu: ipcu@fff50000 {
		compatible = "socionext,ipcu";
		reg = <0xfff50000 0x1000>;
		interrupts = <0 13 4>, <0 14 4>, <0 15 4>, <0 16 4>,
				<0 17 4>, <0 18 4>, <0 19 4>, <0 20 4>,
				<0 21 4>, <0 22 4>, <0 23 4>, <0 24 4>,
				<0 25 4>, <0 26 4>, <0 27 4>, <0 28 4>;
		interrupt-names = "cpuif-0", "cpuif-1", "cpuif-2", "cpuif-3",
			  "cpuif-4", "cpuif-5", "cpuif-6", "cpuif-7",
			  "cpuif-8", "cpuif-9", "cpuif-10", "cpuif-11",
			  "cpuif-12", "cpuif-13", "cpuif-14", "cpuif-15";
		#mbox-cells = <1>;
	};

	ipcu_client0: ipc@0 {
		compatible = "socionext,ipcu_client";
		mboxes = <&ipcu 1>;
	};
	ipcu_client1: ipc@1 {
		compatible = "socionext,ipcu_client";
		mboxes = <&ipcu 3>;
	};
	ipcu_client2: ipc@2 {
		compatible = "socionext,ipcu_client";
		mboxes = <&ipcu 6>;
	};
	ipcu_client3: ipc@3 {
		compatible = "socionext,ipcu_client";
		mboxes = <&ipcu 0>;
	};
	ipcu_client4: ipc@4 {
		compatible = "socionext,ipcu_client";
		mboxes = <&ipcu 2>;
	};
	ipcu_client5: ipc@5 {
		compatible = "socionext,ipcu_client";
		mboxes = <&ipcu 4>;
	};
	ipcu_client6: ipc@6 {
		compatible = "socionext,ipcu_client";
		mboxes = <&ipcu 7>;
	};
	ipcu_client7: ipc@7 {
		compatible = "socionext,ipcu_client";
		mboxes = <&ipcu 5>;
	};
*/

        i2c0 {
                compatible = "socionext,sni2c-v2";
                reg = <0x2c013000 0x400>;
                interrupts = <0 85 4>;
                #address-cells = <1>;
                #size-cells = <0>;
/*                clocks = <&i2cclk>;*/
	};
        i2c1 {
                compatible = "socionext,sni2c-v2";
                reg = <0x2c013400 0x400>;
                interrupts = <0 86 4>;
                #address-cells = <1>;
                #size-cells = <0>;
/*                clocks = <&i2cclk>;*/
	};
        i2c2 {
                compatible = "socionext,sni2c-v2";
                reg = <0x2c013800 0x400>;
                interrupts = <0 87 4>;
                #address-cells = <1>;
                #size-cells = <0>;
/*                clocks = <&i2cclk>;*/
	};

	spi0: usio_spi@2c090000 {
		status = "disabled";
		compatible = "socionext,m8m-usio-spi";
		clocks = <&periphclk>;
		clock-names = "spiclk";
		interrupts = <0 132 4>, <0 133 4>;
		reg = <0x2c090000 0x10>;
		#address-cells = <1>;
		#size-cells = <0>;
		dmas = <&hdmac2 1>, <&hdmac2 0>;
		dma-names = "tx", "rx";
	};
	spi1: usio_spi@2c090010 {
		status = "disabled";
		compatible = "socionext,m8m-usio-spi";
		clocks = <&periphclk>;
		clock-names = "spiclk";
		interrupts = <0 134 4>, <0 135 4>;
		reg = <0x2c090010 0x10>;
		#address-cells = <1>;
		#size-cells = <0>;
		dmas = <&hdmac2 3>, <&hdmac2 2>;
		dma-names = "tx", "rx";
	};
	spi2: usio_spi@2c090020 {
		status = "disabled";
		compatible = "socionext,m8m-usio-spi";
		clocks = <&periphclk>;
		clock-names = "spiclk";
		interrupts = <0 136 4>, <0 137 4>;
		reg = <0x2c090020 0x10>;
		#address-cells = <1>;
		#size-cells = <0>;
		dmas = <&hdmac2 5>, <&hdmac2 4>;
		dma-names = "tx", "rx";
	};
	spi3: usio_spi@2c090030 {
		status = "disabled";
		compatible = "socionext,m8m-usio-spi";
		clocks = <&periphclk>;
		clock-names = "spiclk";
		interrupts = <0 138 4>, <0 139 4>;
		reg = <0x2c090030 0x10>;
		#address-cells = <1>;
		#size-cells = <0>;
		dmas = <&hdmac2 7>, <&hdmac2 6>;
		dma-names = "tx", "rx";
	};
	spi4: usio_spi@2c090040 {
		status = "disabled";
		compatible = "socionext,m8m-usio-spi";
		clocks = <&periphclk>;
		clock-names = "spiclk";
		interrupts = <0 140 4>, <0 141 4>;
		reg = <0x2c090040 0x10>;
		#address-cells = <1>;
		#size-cells = <0>;
		dmas = <&hdmac2 9>, <&hdmac2 8>;
		dma-names = "tx", "rx";
	};
	spi5: usio_spi@2c090050 {
		status = "disabled";
		compatible = "socionext,m8m-usio-spi";
		clocks = <&periphclk>;
		clock-names = "spiclk";
		interrupts = <0 142 4>, <0 143 4>;
		reg = <0x2c090050 0x10>;
		#address-cells = <1>;
		#size-cells = <0>;
		dmas = <&hdmac2 11>, <&hdmac2 10>;
		dma-names = "tx", "rx";
	};

	/* 3-channel i2s controller */

	i2s_rstc: reset-controller@88010000 {
		compatible = "socionext,jmilau8m-rstc";
		reg = <0x2c080000 0x10>;
		#reset-cells = <1>;
	};
	i2s0:i2s@2c080100 {
		compatible = "socionext,jmilau8m";
		reg = <0x2c080100 0x100>,
			<0x18000010 4>; /* special pinmux for unit 0 */
		resets = <&i2s_rstc 0>;
		reset-names = "reset";
/*		clocks = <&aplclk0_gated>,	// main clock 
			 <&aplclk0>,		// set parent... 
			 <&apll_gate_dd>,	// ...to this 
			 <&apll>,		// set this guy's parent... 
			 <&clk2_d125_m128>;	// to this 
			 */
	};
	i2s1:i2s@2c080200 { /* Master for HDMI */
		compatible = "socionext,jmilau8m";
		reg = <0x2c080200 0x100>;
		resets = <&i2s_rstc 1>;
		reset-names = "reset";
/*
		clocks = <&aplclk1_gated>,	// main clock 
			 <&aplclk1>,		// set parent... 
			 <&apll_gate_dd>,	// ...to this 
			 <&apll>,		// set this guy's parent... 
			 <&clk2_d125_m128>;	// to this 
*/
	};
	i2s2:i2s@2c080300 {
		compatible = "socionext,jmilau8m";
		reg = <0x2c080300 0x100>;
		resets = <&i2s_rstc 2>;
		reset-names = "reset";
/*
		clocks = <&aplclk2_gated>;
*/
	};

	pcm0: mb8ac0300_pcm@0 {
                compatible = "socionext,mb8ac0300_pcm";
		dmas = <&hdmac1 0x10 &hdmac1 0x11>;
		dma-names = "capture", "playback";
        };

        alsa: mb86s27_ak4642 {
                compatible = "socionext,mb86s27_ak4642";
                reg = <0 0>; /* fake to stop xx.123 disease */
                channel = <0>;
                sound-dai = <&pcm0>;
		/* todo reset gpio gpios = <&gpio 5 2>; */
        };

	/* hdmi-audio related */

	pcm1: mb8ac0300_pcm@1 {
                compatible = "socionext,mb8ac0300_pcm";
		dmas = <&hdmac1 0x13>;
		dma-names = "playback";
       	};

        f_hdmi_codec: f_hdmi_codec {
                compatible = "socionext,f_hdmi_codec";
                reg = <0 0>;
                sound-dai = <&pcm1>;
        };

        f_hdmi_audio: f_hdmi_audio {
                compatible = "socionext,hdmitx14_audio_card";
                reg = <0 0>;
        };

	/* pwm */

	pwm0: pwm@2c012000 {
		compatible = "socionext,mlb01-pwm";
		reg = <0x2c012000 0x400>, <0x2c040000 0x10000>;
		interrupts = <0 114 4>, <0 117 4>;
		clocks = <&rclk>;
		/* all the pwm units share the same clock */
		base-rate = <13500000>; /* ask for this input rate */
		#pwm-cells = <3>;
	};
	pwm1: pwm@2c012400 {
		compatible = "socionext,mlb01-pwm";
		reg = <0x2c012400 0x400>, <0x2c050000 0x10000>;
		interrupts = <0 115 4>, <0 118 4>;
		clocks = <&rclk>;
		#pwm-cells = <3>;
	};
	pwm2: pwm@2c012800 {
		compatible = "socionext,mlb01-pwm";
		reg = <0x2c012800 0x400>, <0x2c060000 0x10000>;
		interrupts = <0 116 4>, <0 119 4>;
		clocks = <&rclk>;
		#pwm-cells = <3>;
	};
	pwm3: pwm@2c012c00 {
		compatible = "socionext,mlb01-pwm";
		reg = <0x2c012c00 0x400>, <0x2c070000 0x10000>;
		interrupts = <0 120 4>, <0 121 4>;
		clocks = <&rclk>;
		#pwm-cells = <3>;
	};
};
